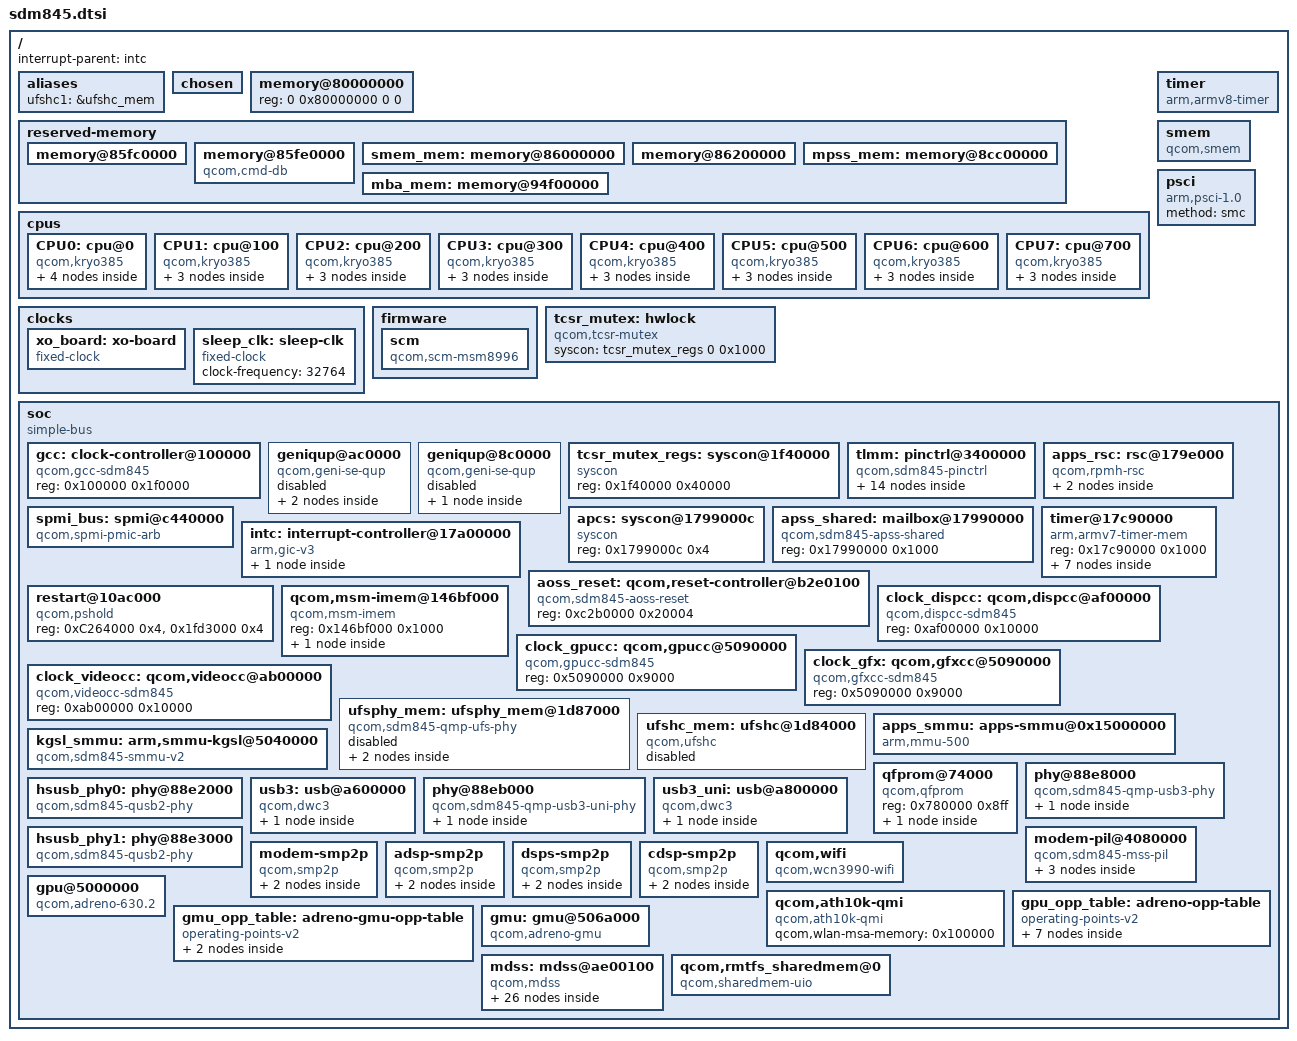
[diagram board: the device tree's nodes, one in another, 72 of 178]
// SPDX-License-Identifier: GPL-2.0
/*
 * SDM845 SoC device tree source
 *
 * Copyright (c) 2018, The Linux Foundation. All rights reserved.
 */

#include <dt-bindings/clock/qcom,gcc-sdm845.h>
#include <dt-bindings/interrupt-controller/arm-gic.h>
#include <dt-bindings/clock/qcom,rpmh.h>
#include <dt-bindings/clock/qcom,dispcc-sdm845.h>
#include <dt-bindings/clock/qcom,gpucc-sdm845.h>
#include <dt-bindings/clock/qcom,videocc-sdm845.h>
#include <dt-bindings/clock/qcom,rpmh.h>
#include <dt-bindings/regulator/qcom,rpmh-regulator.h>
#include <dt-bindings/spmi/spmi.h>
#include <dt-bindings/reset/qcom,sdm845-aoss.h>
#include <dt-bindings/soc/qcom,rpmh-rsc.h>
#include <dt-bindings/msm/msm-bus-ids.h>
#include <dt-bindings/phy/phy-qcom-qusb2.h>

/ {
	interrupt-parent = <&intc>;

	#address-cells = <2>;
	#size-cells = <2>;

	aliases {
		ufshc1 = &ufshc_mem; /* Embedded UFS slot */
	};

	chosen { };

	memory@80000000 {
		device_type = "memory";
		/* We expect the bootloader to fill in the size */
		reg = <0 0x80000000 0 0>;
	};
	reserved-memory {
		#address-cells = <2>;
		#size-cells = <2>;
		ranges;

		memory@85fc0000 {
			reg = <0 0x85fc0000 0 0x20000>;
			no-map;
		};

		memory@85fe0000 {
			compatible = "qcom,cmd-db";
			reg = <0x0 0x85fe0000 0x0 0x20000>;
			no-map;
		};

		smem_mem: memory@86000000 {
			reg = <0x0 0x86000000 0x0 0x200000>;
			no-map;
		};

		memory@86200000 {
			reg = <0 0x86200000 0 0x2d00000>;
			no-map;
		};

		mpss_mem: memory@8cc00000 {
			no-map;
			reg = <0 0x8e000000 0 0x7800000>;
		};

		mba_mem: memory@94f00000 {
			no-map;
			reg = <0 0x96500000 0 0x200000>;
		};
	};

	cpus {
		#address-cells = <2>;
		#size-cells = <0>;

		CPU0: cpu@0 {
			device_type = "cpu";
			compatible = "qcom,kryo385";
			reg = <0x0 0x0>;
			enable-method = "psci";
			efficiency = <1024>;
			next-level-cache = <&L2_0>;

			L2_0: l2-cache {
				compatible = "cache";
				next-level-cache = <&L3_0>;

				L3_0: l3-cache {
				      compatible = "cache";
				};
			};

			L1_I_0: l1-icache {
				compatible = "cache";
				qcom,dump-size = <0x9000>;
			};

			L1_D_0: l1-dcache {
				compatible = "cache";
				qcom,dump-size = <0x9000>;
			};
		};

		CPU1: cpu@100 {
			device_type = "cpu";
			compatible = "qcom,kryo385";
			reg = <0x0 0x100>;
			enable-method = "psci";
			efficiency = <1024>;
			next-level-cache = <&L2_100>;

			L2_100: l2-cache {
			      compatible = "cache";
			      next-level-cache = <&L3_0>;
			};

			L1_I_100: l1-icache {
				compatible = "cache";
				qcom,dump-size = <0x9000>;
			};

			L1_D_100: l1-dcache {
				compatible = "cache";
				qcom,dump-size = <0x9000>;
			};
		};

		CPU2: cpu@200 {
			device_type = "cpu";
			compatible = "qcom,kryo385";
			reg = <0x0 0x200>;
			enable-method = "psci";
			efficiency = <1024>;
			next-level-cache = <&L2_200>;

			L2_200: l2-cache {
			      compatible = "cache";
			      next-level-cache = <&L3_0>;
			};

			L1_I_200: l1-icache {
				compatible = "cache";
				qcom,dump-size = <0x9000>;
			};

			L1_D_200: l1-dcache {
				compatible = "cache";
				qcom,dump-size = <0x9000>;
			};
		};

		CPU3: cpu@300 {
			device_type = "cpu";
			compatible = "qcom,kryo385";
			reg = <0x0 0x300>;
			enable-method = "psci";
			efficiency = <1024>;
			next-level-cache = <&L2_300>;

			L2_300: l2-cache {
			      compatible = "cache";
			      next-level-cache = <&L3_0>;
			};

			L1_I_300: l1-icache {
				compatible = "cache";
				qcom,dump-size = <0x9000>;
			};
			L1_D_300: l1-dcache {
				compatible = "cache";
				qcom,dump-size = <0x9000>;
			};
		};

		CPU4: cpu@400 {
			device_type = "cpu";
			compatible = "qcom,kryo385";
			reg = <0x0 0x400>;
			enable-method = "psci";
			efficiency = <1740>;
			next-level-cache = <&L2_400>;

			L2_400: l2-cache {
			      compatible = "cache";
			      next-level-cache = <&L3_0>;
			};

			L1_I_400: l1-icache {
				compatible = "cache";
				qcom,dump-size = <0x12000>;
			};

			L1_D_400: l1-dcache {
				compatible = "cache";
				qcom,dump-size = <0x12000>;
			};
		};

		CPU5: cpu@500 {
			device_type = "cpu";
			compatible = "qcom,kryo385";
			reg = <0x0 0x500>;
			enable-method = "psci";
			efficiency = <1740>;
			next-level-cache = <&L2_500>;

			L2_500: l2-cache {
			      compatible = "cache";
			      next-level-cache = <&L3_0>;
			};

			L1_I_500: l1-icache {
				compatible = "cache";
				qcom,dump-size = <0x12000>;
			};

			L1_D_500: l1-dcache {
				compatible = "cache";
				qcom,dump-size = <0x12000>;
			};
		};

		CPU6: cpu@600 {
			device_type = "cpu";
			compatible = "qcom,kryo385";
			reg = <0x0 0x600>;
			enable-method = "psci";
			efficiency = <1740>;
			next-level-cache = <&L2_600>;

			L2_600: l2-cache {
			      compatible = "cache";
			      next-level-cache = <&L3_0>;
			};

			L1_I_600: l1-icache {
				compatible = "cache";
				qcom,dump-size = <0x12000>;
			};

			L1_D_600: l1-dcache {
				compatible = "cache";
				qcom,dump-size = <0x12000>;
			};
		};

		CPU7: cpu@700 {
			device_type = "cpu";
			compatible = "qcom,kryo385";
			reg = <0x0 0x700>;
			enable-method = "psci";
			efficiency = <1740>;
			next-level-cache = <&L2_700>;

			L2_700: l2-cache {
			      compatible = "cache";
			      next-level-cache = <&L3_0>;
			};

			L1_I_700: l1-icache {
				compatible = "cache";
				qcom,dump-size = <0x12000>;
			};

			L1_D_700: l1-dcache {
				compatible = "cache";
				qcom,dump-size = <0x12000>;
		};
		};
	};

	timer {
		compatible = "arm,armv8-timer";
		interrupts = <GIC_PPI 1 IRQ_TYPE_LEVEL_LOW>,
			     <GIC_PPI 2 IRQ_TYPE_LEVEL_LOW>,
			     <GIC_PPI 3 IRQ_TYPE_LEVEL_LOW>,
			     <GIC_PPI 0 IRQ_TYPE_LEVEL_LOW>;
	};

	clocks {
		xo_board: xo-board {
			compatible = "fixed-clock";
			#clock-cells = <0>;
			clock-frequency = <38400000>;
			clock-output-names = "xo_board";
		};

		sleep_clk: sleep-clk {
			compatible = "fixed-clock";
			#clock-cells = <0>;
			clock-frequency = <32764>;
		};
	};

	firmware {
		scm {
			compatible = "qcom,scm-msm8996";
		};
	};

	tcsr_mutex: hwlock {
		compatible = "qcom,tcsr-mutex";
		syscon = <&tcsr_mutex_regs 0 0x1000>;
		#hwlock-cells = <1>;
	};

	smem {
		compatible = "qcom,smem";
		memory-region = <&smem_mem>;
		hwlocks = <&tcsr_mutex 3>;
	};

	psci {
		compatible = "arm,psci-1.0";
		method = "smc";
	};

	soc: soc {
		#address-cells = <1>;
		#size-cells = <1>;
		ranges = <0 0 0 0xffffffff>;
		compatible = "simple-bus";

		gcc: clock-controller@100000 {
			compatible = "qcom,gcc-sdm845";
			reg = <0x100000 0x1f0000>;
			#clock-cells = <1>;
			#reset-cells = <1>;
			#power-domain-cells = <1>;
		};

		geniqup@ac0000 {
			compatible = "qcom,geni-se-qup";
			reg = <0xac0000 0x6000>;
			clock-names = "m-ahb", "s-ahb";
			clocks = <&gcc GCC_QUPV3_WRAP_1_M_AHB_CLK>,
				 <&gcc GCC_QUPV3_WRAP_1_S_AHB_CLK>;
			#address-cells = <1>;
			#size-cells = <1>;
			ranges;
			status = "disabled";

			uart2: serial@a84000 {
				compatible = "qcom,geni-debug-uart";
				reg = <0xa84000 0x4000>;
				clock-names = "se";
				clocks = <&gcc GCC_QUPV3_WRAP1_S1_CLK>;
				pinctrl-names = "default", "sleep";
				pinctrl-0 = <&qup_uart2_default>;
				pinctrl-1 = <&qup_uart2_sleep>;
				interrupts = <GIC_SPI 354 IRQ_TYPE_LEVEL_HIGH>;
				status = "disabled";
			};

			i2c10: i2c@a88000 {
				compatible = "qcom,geni-i2c";
				reg = <0xa88000 0x4000>;
				clock-names = "se";
				clocks = <&gcc GCC_QUPV3_WRAP1_S2_CLK>;
				pinctrl-names = "default", "sleep";
				pinctrl-0 = <&qup_i2c10_default>;
				pinctrl-1 = <&qup_i2c10_sleep>;
				interrupts = <GIC_SPI 355 IRQ_TYPE_LEVEL_HIGH>;
				#address-cells = <1>;
				#size-cells = <0>;
				status = "disabled";
			};
		};

		geniqup@8c0000 {
			compatible = "qcom,geni-se-qup";
			reg = <0x8c0000 0x6000>;
			clock-names = "m-ahb", "s-ahb";
			clocks = <&gcc GCC_QUPV3_WRAP_0_M_AHB_CLK>,
				<&gcc GCC_QUPV3_WRAP_0_S_AHB_CLK>;
			#address-cells = <1>;
			#size-cells = <1>;
			ranges;
			status = "disabled";

			uart6: serial@898000 {
				compatible = "qcom,geni-uart";
				reg = <0x898000 0x4000>;
				clock-names = "se";
				clocks = <&gcc GCC_QUPV3_WRAP0_S6_CLK>;
				interrupts = <GIC_SPI 607 IRQ_TYPE_LEVEL_HIGH>;
				pinctrl-names = "default", "sleep";
				pinctrl-0 = <&qup_uart6_default>;
				pinctrl-1 = <&qup_uart6_sleep>;
				status = "disabled";
			};
		};

		tcsr_mutex_regs: syscon@1f40000 {
			compatible = "syscon";
			reg = <0x1f40000 0x40000>;
		};

		tlmm: pinctrl@3400000 {
			compatible = "qcom,sdm845-pinctrl";
			reg = <0x03400000 0xc00000>;
			interrupts = <GIC_SPI 208 IRQ_TYPE_NONE>;
			gpio-controller;
			#gpio-cells = <2>;
			interrupt-controller;
			#interrupt-cells = <2>;

			qup_i2c10_default: qup-i2c10-default {
				pinmux {
					function = "qup10";
					pins = "gpio55", "gpio56";
				};
			};

			qup_i2c10_sleep: qup-i2c10-sleep {
				pinmux {
					function = "gpio";
					pins = "gpio55", "gpio56";
				};
			};

			qup_uart2_default: qup-uart2-default {
				pinmux {
					function = "qup9";
					pins = "gpio4", "gpio5";
				};
			};

			qup_uart2_sleep: qup-uart2-sleep {
				pinmux {
					function = "gpio";
					pins = "gpio4", "gpio5";
				};
			};

			qup_uart6_default: qup-uart6-default {
				pinmux {
					function = "qup6";
					pins = "gpio45", "gpio46",
							"gpio47", "gpio48";
				};

				pinconf {
					pins = "gpio45", "gpio46",
							"gpio47", "gpio48";
					drive-strength = <2>;
					bias-no-pull;
				};
			};

			qup_uart6_sleep: qup-uart6-sleep {
				pinmux {
					function = "gpio";
					pins = "gpio45", "gpio46",
							"gpio47", "gpio48";
				};

				pinconf_ctsrx {
					pins = "gpio45", "gpio46",
							"gpio47", "gpio48";
					bias-no-pull;
				};
			};
		};

	        apps_rsc: rsc@179e000 {
			compatible = "qcom,rpmh-rsc";
			label = "apps_rsc";
			reg = <0x179e0000 0x100>, <0x179e0d00 0x3000>;
			reg-names = "drv", "tcs";
			interrupts = <GIC_SPI 5 IRQ_TYPE_LEVEL_HIGH>;
			qcom,drv-id = <2>;
			qcom,tcs-config = <ACTIVE_TCS  2>,
					  <SLEEP_TCS   3>,
					  <WAKE_TCS    3>,
					  <CONTROL_TCS 1>;

			msm_bus_apps_rsc {
				compatible = "qcom,msm-bus-rsc";
				qcom,msm-bus-id = <MSM_BUS_RSC_APPS>;
			};
		};

		spmi_bus: spmi@c440000 {
			compatible = "qcom,spmi-pmic-arb";
			reg = <0xc440000 0x1100>,
			      <0xc600000 0x2000000>,
			      <0xe600000 0x100000>,
			      <0xe700000 0xa0000>,
			      <0xc40a000 0x26000>;
			reg-names = "core", "chnls", "obsrvr", "intr", "cnfg";
			interrupt-names = "periph_irq";
			interrupts = <GIC_SPI 481 IRQ_TYPE_LEVEL_HIGH>;
			qcom,ee = <0>;
			qcom,channel = <0>;
			#address-cells = <2>;
			#size-cells = <0>;
			interrupt-controller;
			#interrupt-cells = <4>;
			cell-index = <0>;
		};

		apcs: syscon@1799000c {
			compatible = "syscon";
			reg = <0x1799000c 0x4>;
		};

		apss_shared: mailbox@17990000 {
			compatible = "qcom,sdm845-apss-shared";
			reg = <0x17990000 0x1000>;
			#mbox-cells = <1>;
		};

		intc: interrupt-controller@17a00000 {
			compatible = "arm,gic-v3";
			#address-cells = <1>;
			#size-cells = <1>;
			ranges;
			#interrupt-cells = <3>;
			interrupt-controller;
			reg = <0x17a00000 0x10000>,     /* GICD */
			      <0x17a60000 0x100000>;    /* GICR * 8 */
			interrupts = <GIC_PPI 9 IRQ_TYPE_LEVEL_HIGH>;

			gic-its@17a40000 {
				compatible = "arm,gic-v3-its";
				msi-controller;
				#msi-cells = <1>;
				reg = <0x17a40000 0x20000>;
				status = "disabled";
			};
		};

		timer@17c90000 {
			#address-cells = <1>;
			#size-cells = <1>;
			ranges;
			compatible = "arm,armv7-timer-mem";
			reg = <0x17c90000 0x1000>;

			frame@17ca0000 {
				frame-number = <0>;
				interrupts = <GIC_SPI 7 IRQ_TYPE_LEVEL_HIGH>,
					     <GIC_SPI 6 IRQ_TYPE_LEVEL_HIGH>;
				reg = <0x17ca0000 0x1000>,
				      <0x17cb0000 0x1000>;
			};

			frame@17cc0000 {
				frame-number = <1>;
				interrupts = <GIC_SPI 8 IRQ_TYPE_LEVEL_HIGH>;
				reg = <0x17cc0000 0x1000>;
				status = "disabled";
			};

			frame@17cd0000 {
				frame-number = <2>;
				interrupts = <GIC_SPI 9 IRQ_TYPE_LEVEL_HIGH>;
				reg = <0x17cd0000 0x1000>;
				status = "disabled";
			};

			frame@17ce0000 {
				frame-number = <3>;
				interrupts = <GIC_SPI 10 IRQ_TYPE_LEVEL_HIGH>;
				reg = <0x17ce0000 0x1000>;
				status = "disabled";
			};

			frame@17cf0000 {
				frame-number = <4>;
				interrupts = <GIC_SPI 11 IRQ_TYPE_LEVEL_HIGH>;
				reg = <0x17cf0000 0x1000>;
				status = "disabled";
			};

			frame@17d00000 {
				frame-number = <5>;
				interrupts = <GIC_SPI 12 IRQ_TYPE_LEVEL_HIGH>;
				reg = <0x17d00000 0x1000>;
				status = "disabled";
			};

			frame@17d10000 {
				frame-number = <6>;
				interrupts = <GIC_SPI 13 IRQ_TYPE_LEVEL_HIGH>;
				reg = <0x17d10000 0x1000>;
				status = "disabled";
			};
		};

		aoss_reset: qcom,reset-controller@b2e0100 {
			compatible = "qcom,sdm845-aoss-reset";
			reg = <0xc2b0000 0x20004>;
			#reset-cells = <1>;
		};

	restart@10ac000 {
		compatible = "qcom,pshold";
		reg = <0xC264000 0x4>,
		      <0x1fd3000 0x4>;
		reg-names = "pshold-base", "tcsr-boot-misc-detect";
	};

	qcom,msm-imem@146bf000 {
		compatible = "qcom,msm-imem";
		reg = <0x146bf000 0x1000>;
		ranges = <0x0 0x146bf000 0x1000>;
		#address-cells = <1>;
		#size-cells = <1>;

		restart_reason@65c {
			compatible = "qcom,msm-imem-restart_reason";
			reg = <0x65c 4>;
		};
	};

		clock_dispcc: qcom,dispcc@af00000 {
			compatible = "qcom,dispcc-sdm845", "syscon";
			reg = <0xaf00000 0x10000>;
			reg-names = "cc_base";
			#clock-cells = <1>;
			#reset-cells = <1>;
			#power-domain-cells = <1>;
		};

		clock_gpucc: qcom,gpucc@5090000 {
			compatible = "qcom,gpucc-sdm845", "syscon";
			reg = <0x5090000 0x9000>;
			reg-names = "cc_base";
			#clock-cells = <1>;
			#reset-cells = <1>;
			#power-domain-cells = <1>;
		};

		clock_gfx: qcom,gfxcc@5090000 {
			compatible = "qcom,gfxcc-sdm845";
			reg = <0x5090000 0x9000>;
			reg-names = "cc_base";
			#clock-cells = <1>;
			#reset-cells = <1>;
		};

		clock_videocc: qcom,videocc@ab00000 {
			compatible = "qcom,videocc-sdm845", "syscon";
			reg = <0xab00000 0x10000>;
			reg-names = "cc_base";
			#clock-cells = <1>;
			#reset-cells = <1>;
			#power-domain-cells = <1>;
		};

		ufsphy_mem: ufsphy_mem@1d87000 {
			compatible = "qcom,sdm845-qmp-ufs-phy";
			reg = <0x1d87000 0x18c>; /* PHY regs */
			#clock-cells = <1>;
			#address-cells = <1>;
			#size-cells = <1>;
			ranges;
			clock-names = "ref_clk_src",
				"ref_clk",
				"ref_aux_clk";
			clocks = <&clock_rpmh RPMH_CXO_CLK>,
				<&gcc GCC_UFS_MEM_CLKREF_CLK>,
				<&gcc GCC_UFS_PHY_PHY_AUX_CLK>;

			status = "disabled";

			ufsphy_0: lane@0x1d87400 {
				reg = <0x1d87400 0x108>,
					<0x1d87600 0x1e0>,
					<0x1d87c00 0x1dc>;
				#phy-cells = <0>;
			};

			ufsphy_1: lane@0x1d87800 {
				reg = <0x1d87800 0x108>,
					<0x1d87a00 0x1e0>,
					<0x1d87c00 0x1dc>;
				#phy-cells = <0>;
			};
		};

		ufshc_mem: ufshc@1d84000 {
			compatible = "qcom,ufshc";
			reg = <0x1d84000 0x2500>;
			interrupts = <0 265 0>;
			phys = <&ufsphy_0>, <&ufsphy_1>;
			phy-names = "ufsphy_0", "ufsphy_1";

			lanes-per-direction = <2>;
			dev-ref-clk-freq = <0>; /* 19.2 MHz */

			power-domains = <&gcc UFS_PHY_GDSC>;

			clock-names =
				"core_clk",
				"bus_aggr_clk",
				"iface_clk",
				"core_clk_unipro",
				"ref_clk",
				"tx_lane0_sync_clk",
				"rx_lane0_sync_clk",
				"rx_lane1_sync_clk";
			clocks =
				<&gcc GCC_UFS_PHY_AXI_CLK>,
				<&gcc GCC_AGGRE_UFS_PHY_AXI_CLK>,
				<&gcc GCC_UFS_PHY_AHB_CLK>,
				<&gcc GCC_UFS_PHY_UNIPRO_CORE_CLK>,
				<&clock_rpmh RPMH_CXO_CLK>,
				<&gcc GCC_UFS_PHY_TX_SYMBOL_0_CLK>,
				<&gcc GCC_UFS_PHY_RX_SYMBOL_0_CLK>,
				<&gcc GCC_UFS_PHY_RX_SYMBOL_1_CLK>;
			freq-table-hz =
				<50000000 200000000>,
				<0 0>,
				<0 0>,
				<37500000 150000000>,
				<0 0>,
				<0 0>,
				<0 0>,
				<0 0>;

			non-removable;
			pinctrl-names = "dev-reset-assert", "dev-reset-deassert";
			pinctrl-0 = <&ufs_dev_reset_assert>;
			pinctrl-1 = <&ufs_dev_reset_deassert>;

			resets = <&gcc GCC_UFS_PHY_BCR>;
			reset-names = "core_reset";

			status = "disabled";
		};

		apps_smmu: apps-smmu@0x15000000 {
			compatible = "arm,mmu-500";
			reg = <0x15000000 0x80000>;
			#iommu-cells = <2>;
			#global-interrupts = <1>;

			interrupts =	<GIC_SPI 65 IRQ_TYPE_LEVEL_HIGH>,
					<GIC_SPI 96 IRQ_TYPE_LEVEL_HIGH>,
					<GIC_SPI 97 IRQ_TYPE_LEVEL_HIGH>,
					<GIC_SPI 98 IRQ_TYPE_LEVEL_HIGH>,
					<GIC_SPI 99 IRQ_TYPE_LEVEL_HIGH>,
					<GIC_SPI 100 IRQ_TYPE_LEVEL_HIGH>,
					<GIC_SPI 101 IRQ_TYPE_LEVEL_HIGH>,
					<GIC_SPI 102 IRQ_TYPE_LEVEL_HIGH>,
					<GIC_SPI 103 IRQ_TYPE_LEVEL_HIGH>,
					<GIC_SPI 104 IRQ_TYPE_LEVEL_HIGH>,
					<GIC_SPI 105 IRQ_TYPE_LEVEL_HIGH>,
					<GIC_SPI 106 IRQ_TYPE_LEVEL_HIGH>,
					<GIC_SPI 107 IRQ_TYPE_LEVEL_HIGH>,
					<GIC_SPI 108 IRQ_TYPE_LEVEL_HIGH>,
					<GIC_SPI 109 IRQ_TYPE_LEVEL_HIGH>,
					<GIC_SPI 110 IRQ_TYPE_LEVEL_HIGH>,
					<GIC_SPI 111 IRQ_TYPE_LEVEL_HIGH>,
					<GIC_SPI 112 IRQ_TYPE_LEVEL_HIGH>,
					<GIC_SPI 113 IRQ_TYPE_LEVEL_HIGH>,
					<GIC_SPI 114 IRQ_TYPE_LEVEL_HIGH>,
					<GIC_SPI 115 IRQ_TYPE_LEVEL_HIGH>,
					<GIC_SPI 116 IRQ_TYPE_LEVEL_HIGH>,
					<GIC_SPI 117 IRQ_TYPE_LEVEL_HIGH>,
					<GIC_SPI 118 IRQ_TYPE_LEVEL_HIGH>,
					<GIC_SPI 181 IRQ_TYPE_LEVEL_HIGH>,
					<GIC_SPI 182 IRQ_TYPE_LEVEL_HIGH>,
					<GIC_SPI 183 IRQ_TYPE_LEVEL_HIGH>,
					<GIC_SPI 184 IRQ_TYPE_LEVEL_HIGH>,
					<GIC_SPI 185 IRQ_TYPE_LEVEL_HIGH>,
					<GIC_SPI 186 IRQ_TYPE_LEVEL_HIGH>,
					<GIC_SPI 187 IRQ_TYPE_LEVEL_HIGH>,
					<GIC_SPI 188 IRQ_TYPE_LEVEL_HIGH>,
					<GIC_SPI 189 IRQ_TYPE_LEVEL_HIGH>,
					<GIC_SPI 190 IRQ_TYPE_LEVEL_HIGH>,
					<GIC_SPI 191 IRQ_TYPE_LEVEL_HIGH>,
					<GIC_SPI 192 IRQ_TYPE_LEVEL_HIGH>,
					<GIC_SPI 315 IRQ_TYPE_LEVEL_HIGH>,
					<GIC_SPI 316 IRQ_TYPE_LEVEL_HIGH>,
					<GIC_SPI 317 IRQ_TYPE_LEVEL_HIGH>,
					<GIC_SPI 318 IRQ_TYPE_LEVEL_HIGH>,
					<GIC_SPI 319 IRQ_TYPE_LEVEL_HIGH>,
					<GIC_SPI 320 IRQ_TYPE_LEVEL_HIGH>,
					<GIC_SPI 321 IRQ_TYPE_LEVEL_HIGH>,
					<GIC_SPI 322 IRQ_TYPE_LEVEL_HIGH>,
					<GIC_SPI 323 IRQ_TYPE_LEVEL_HIGH>,
					<GIC_SPI 324 IRQ_TYPE_LEVEL_HIGH>,
					<GIC_SPI 325 IRQ_TYPE_LEVEL_HIGH>,
					<GIC_SPI 326 IRQ_TYPE_LEVEL_HIGH>,
					<GIC_SPI 327 IRQ_TYPE_LEVEL_HIGH>,
					<GIC_SPI 328 IRQ_TYPE_LEVEL_HIGH>,
					<GIC_SPI 329 IRQ_TYPE_LEVEL_HIGH>,
					<GIC_SPI 330 IRQ_TYPE_LEVEL_HIGH>,
					<GIC_SPI 331 IRQ_TYPE_LEVEL_HIGH>,
					<GIC_SPI 332 IRQ_TYPE_LEVEL_HIGH>,
					<GIC_SPI 333 IRQ_TYPE_LEVEL_HIGH>,
					<GIC_SPI 334 IRQ_TYPE_LEVEL_HIGH>,
					<GIC_SPI 335 IRQ_TYPE_LEVEL_HIGH>,
					<GIC_SPI 336 IRQ_TYPE_LEVEL_HIGH>,
					<GIC_SPI 337 IRQ_TYPE_LEVEL_HIGH>,
					<GIC_SPI 338 IRQ_TYPE_LEVEL_HIGH>,
					<GIC_SPI 339 IRQ_TYPE_LEVEL_HIGH>,
					<GIC_SPI 340 IRQ_TYPE_LEVEL_HIGH>,
					<GIC_SPI 341 IRQ_TYPE_LEVEL_HIGH>,
					<GIC_SPI 342 IRQ_TYPE_LEVEL_HIGH>,
					<GIC_SPI 343 IRQ_TYPE_LEVEL_HIGH>;
		};

		kgsl_smmu: arm,smmu-kgsl@5040000 {
			compatible = "qcom,sdm845-smmu-v2", "qcom,smmu-v2";
			reg = <0x5040000 0x10000>;
			#iommu-cells = <1>;
			#global-interrupts = <2>;
			interrupts = <GIC_SPI 229 IRQ_TYPE_LEVEL_HIGH>,
					<GIC_SPI 231 IRQ_TYPE_LEVEL_HIGH>,
					<GIC_SPI 364 IRQ_TYPE_EDGE_RISING>,
					<GIC_SPI 365 IRQ_TYPE_EDGE_RISING>,
					<GIC_SPI 366 IRQ_TYPE_EDGE_RISING>,
					<GIC_SPI 367 IRQ_TYPE_EDGE_RISING>,
					<GIC_SPI 368 IRQ_TYPE_EDGE_RISING>,
					<GIC_SPI 369 IRQ_TYPE_EDGE_RISING>,
					<GIC_SPI 370 IRQ_TYPE_EDGE_RISING>,
					<GIC_SPI 371 IRQ_TYPE_EDGE_RISING>;
			clocks = <&gcc GCC_GPU_MEMNOC_GFX_CLK>,
				<&gcc GCC_GPU_CFG_AHB_CLK>;
			clock-names = "bus", "iface";

			power-domains = <&clock_gpucc GPU_CX_GDSC>;
		};

		qfprom@74000 {
			compatible = "qcom,qfprom";
			reg = <0x780000 0x8ff>;
			#address-cells = <1>;
			#size-cells = <1>;
			qusb2p_hstx_trim: hstx_trim@1eb {
				reg = <0x1eb 0x1>;
				bits = <1 4>;
			};
		};

		phy@88e8000 {
			compatible = "qcom,sdm845-qmp-usb3-phy";
			reg = <0x88e9000 0x18c>,
				<0x88e8000 0x10>; /*dp_com */
			reg-names = "reg-base", "dp_com";
			#clock-cells = <1>;
			#address-cells = <1>;
			#size-cells = <1>;
			ranges;

			clocks = <&gcc GCC_USB3_PRIM_PHY_AUX_CLK>,
				<&gcc GCC_USB_PHY_CFG_AHB2PHY_CLK>,
				<&gcc GCC_USB3_PRIM_CLKREF_CLK>,
				<&gcc GCC_USB3_PRIM_PHY_COM_AUX_CLK>;

			clock-names = "aux", "cfg_ahb", "ref", "com_aux";

			vdda-phy-supply = <&pm8998_l26>;
			vdda-pll-supply = <&pm8998_l1>;

			resets = <&gcc GCC_USB3_DP_PHY_PRIM_BCR>,
				<&gcc GCC_USB3_PHY_PRIM_BCR>;
			reset-names = "phy", "common";

			ssusb_phy_0: lane@88e9200 {
				reg = <0x88e9200 0x128>,
					<0x88e9400 0x200>,
					<0x88e9c00 0x218>,
					<0x88e9a00 0x100>;
				reg-names = "tx", "rx", "pcs", "pcs_misc";
				#phy-cells = <0>;
				clocks = <&gcc GCC_USB3_PRIM_PHY_PIPE_CLK>;
				clock-names = "pipe0";
				clock-output-names = "usb3_phy_pipe_clk_src";
			};
		};

		hsusb_phy0: phy@88e2000 {
			compatible = "qcom,sdm845-qusb2-phy";
			reg = <0x88e2000 0x400>;
			reg-names = "reg-base";
			#phy-cells = <0>;

			clocks = <&gcc GCC_USB_PHY_CFG_AHB2PHY_CLK>,
				<&clock_rpmh RPMH_CXO_CLK>;
			clock-names = "cfg_ahb", "ref";

			vdd-supply = <&pm8998_l1>;
			vdda-pll-supply = <&pm8998_l12>;
			vdda-phy-dpdm-supply = <&pm8998_l24>;
			resets = <&gcc GCC_QUSB2PHY_PRIM_BCR>;
			nvmem-cells = <&qusb2p_hstx_trim>;

			qcom,imp-res-offset-value = <8>;
			qcom,hstx-trim-value = <QUSB2_V2_HSTX_TRIM_21_6_MA>;
			qcom,preemphasis-level = <QUSB2_V2_PREEMPHASIS_5_PERCENT>;
			qcom,preemphasis-width = <QUSB2_V2_PREEMPHASIS_WIDTH_HALF_BIT>;
		};

		usb3: usb@a600000 {
			compatible = "qcom,dwc3";
			reg = <0xa6f8800 0x400>;
			reg-names = "qscratch";
			#address-cells = <1>;
			#size-cells = <1>;
			ranges;

			interrupts = <0 131 0>, <0 486 0>, <0 488 0>, <0 489 0>;
			interrupt-names = "hs_phy_irq", "ss_phy_irq",
					  "dm_hs_phy_irq", "dp_hs_phy_irq";

			clocks = <&gcc GCC_CFG_NOC_USB3_PRIM_AXI_CLK>,
				<&gcc GCC_USB30_PRIM_MASTER_CLK>,
				<&gcc GCC_AGGRE_USB3_PRIM_AXI_CLK>,
				<&gcc GCC_USB30_PRIM_MOCK_UTMI_CLK>,
				<&gcc GCC_USB30_PRIM_SLEEP_CLK>,
				<&gcc GCC_USB_PHY_CFG_AHB2PHY_CLK>,
				<&gcc GCC_USB3_PRIM_CLKREF_CLK>;
			clock-names = "cfg_noc", "core", "aggr_noc", "utmi",
					"sleep", "cfg_ahb", "ref";

			assigned-clocks = <&gcc GCC_USB30_PRIM_MOCK_UTMI_CLK>,
					  <&gcc GCC_USB30_PRIM_MASTER_CLK>;
			assigned-clock-rates = <19200000>, <150000000>;

			resets = <&gcc GCC_USB30_PRIM_BCR>;
			reset-names = "core_reset";
			power-domains = <&gcc USB30_PRIM_GDSC>;

			dwc3@6a00000 {
				compatible = "snps,dwc3";
				reg = <0xa600000 0xcd00>;
				interrupts = <0 133 0>;
				snps,disable-clk-gating;
				snps,dis_u2_susphy_quirk;
				snps,dis_enblslpm_quirk;
				phys = <&hsusb_phy0>, <&ssusb_phy_0>;
				phy-names = "usb2-phy", "usb3-phy";
				dr_mode = "host";
			};
		};

		phy@88eb000 {
			compatible = "qcom,sdm845-qmp-usb3-uni-phy";
			reg = <0x88eb000 0x18c>;
			reg-names = "reg-base";
			#clock-cells = <1>;
			#address-cells = <1>;
			#size-cells = <1>;
			ranges;

			clocks = <&gcc GCC_USB3_SEC_PHY_AUX_CLK>,
				<&gcc GCC_USB_PHY_CFG_AHB2PHY_CLK>,
				<&gcc GCC_USB3_SEC_CLKREF_CLK>,
				<&gcc GCC_USB3_SEC_PHY_COM_AUX_CLK>;

			clock-names = "aux", "cfg_ahb", "ref", "com_aux";

			vdda-phy-supply = <&pm8998_l26>;
			vdda-pll-supply = <&pm8998_l1>;

			resets = <&gcc GCC_USB3PHY_PHY_SEC_BCR>,
				<&gcc GCC_USB3_PHY_SEC_BCR>;
			reset-names = "phy", "common";

			ssusb_phy_1: lane@88eb200 {
				reg = <0x88eb200 0x128>,
					<0x88eb400 0x1fc>,
					<0x88eb800 0x218>,
					<0x88eb600 0x70>;
				reg-names = "tx", "rx", "pcs", "pcs_misc";
				#phy-cells = <0>;
				clocks = <&gcc GCC_USB3_SEC_PHY_PIPE_CLK>;
				clock-names = "pipe0";
				clock-output-names = "usb3_uniphy_pipe_clk_src";
			};
		};

		hsusb_phy1: phy@88e3000 {
			compatible = "qcom,sdm845-qusb2-phy";
			reg = <0x88e3000 0x400>;
			reg-names = "reg-base";
			#phy-cells = <0>;

			clocks = <&gcc GCC_USB_PHY_CFG_AHB2PHY_CLK>,
				<&clock_rpmh RPMH_CXO_CLK>;
			clock-names = "cfg_ahb", "ref";

			vdd-supply = <&pm8998_l1>;
			vdda-pll-supply = <&pm8998_l12>;
			vdda-phy-dpdm-supply = <&pm8998_l24>;

			resets = <&gcc GCC_QUSB2PHY_SEC_BCR>;

			qcom,imp-res-offset-value = <8>;
			qcom,hstx-trim-value = <QUSB2_V2_HSTX_TRIM_22_8_MA>;
		};

		/* USB3 Secondary controller with QMP UNI-PHY */
		usb3_uni: usb@a800000 {
			compatible = "qcom,dwc3";
			reg = <0xa8f8800 0x400>;
			reg-names = "qscratch";
			#address-cells = <1>;
			#size-cells = <1>;
			ranges;

			interrupts = <0 136 0>, <0 487 0>, <0 490 0>, <0 491 0>;
			interrupt-names = "hs_phy_irq", "ss_phy_irq",
					  "dm_hs_phy_irq", "dp_hs_phy_irq";

			clocks = <&gcc GCC_CFG_NOC_USB3_SEC_AXI_CLK>,
				<&gcc GCC_USB30_SEC_MASTER_CLK>,
				<&gcc GCC_AGGRE_USB3_SEC_AXI_CLK>,
				<&gcc GCC_USB30_SEC_MOCK_UTMI_CLK>,
				<&gcc GCC_USB30_SEC_SLEEP_CLK>,
				<&gcc GCC_USB_PHY_CFG_AHB2PHY_CLK>,
				<&gcc GCC_USB3_SEC_CLKREF_CLK>;
			clock-names = "cfg_noc", "core", "aggr_noc", "utmi",
					"sleep", "cfg_ahb", "ref";

			assigned-clocks = <&gcc GCC_USB30_SEC_MOCK_UTMI_CLK>,
					  <&gcc GCC_USB30_SEC_MASTER_CLK>;
			assigned-clock-rates = <19200000>, <150000000>;

			resets = <&gcc GCC_USB30_SEC_BCR>;
			reset-names = "core_reset";
			power-domains = <&gcc USB30_SEC_GDSC>;

			dwc3@a800000 {
				compatible = "snps,dwc3";
				reg = <0xa800000 0xcd00>;
				interrupts = <0 138 0>;
				snps,disable-clk-gating;
				snps,dis_u2_susphy_quirk;
				snps,dis_enblslpm_quirk;
				phys = <&hsusb_phy1>, <&ssusb_phy_1>;
				phy-names = "usb2-phy", "usb3-phy";
				dr_mode = "peripheral";
			};
		};

		modem-pil@4080000 {
			compatible = "qcom,sdm845-mss-pil";
			reg = <0x04080000 0x408>, <0x04180000 0x48>;

			reg-names = "qdsp6", "rmb";

			interrupts-extended = <&intc 0 266 1>,
					      <&modem_smp2p_in 0 0>,
					      <&modem_smp2p_in 1 0>,
					      <&modem_smp2p_in 2 0>,
					      <&modem_smp2p_in 3 0>;

			interrupt-names = "wdog", "fatal", "ready",
					  "handover", "stop-ack";

			clocks = <&gcc GCC_MSS_CFG_AHB_CLK>,
				 <&gcc GCC_MSS_Q6_MEMNOC_AXI_CLK>,
				 <&gcc GCC_BOOT_ROM_AHB_CLK>,
				 <&gcc GCC_MSS_GPLL0_DIV_CLK_SRC>,
				 <&gcc GCC_MSS_SNOC_AXI_CLK>,
				 <&gcc GCC_MSS_AXIS2_CLK>,
				 <&gcc GCC_MSS_MFAB_AXIS_CLK>,
				 <&gcc GCC_PRNG_AHB_CLK>,
				 <&xo_board>;

			clock-names = "iface", "bus", "mem", "gpll0_mss",
				      "snoc_axi", "axis2", "mnoc_axi",
				      "prng", "xo";

			qcom,smem-states = <&modem_smp2p_out 0>;
			qcom,smem-state-names = "stop";

			resets = <&aoss_reset AOSS_CC_MSS_RESTART>;
			reset-names = "mss_restart";

			cx-supply = <&pm8998_s9_level>;
			mx-supply = <&pm8998_s6_level>;
			mss-supply = <&pm8005_s2_level>;

			qcom,halt-regs = <&tcsr_mutex_regs
						0x23000 0x25000 0x24000>;

			mba {
				memory-region = <&mba_mem>;
			};

			mpss {
				memory-region = <&mpss_mem>;
			};

			glink-edge {
				interrupts = <0 449 IRQ_TYPE_EDGE_RISING>;
				label = "modem";
				qcom,remote-pid = <1>;
				mboxes = <&apss_shared 12>;
				mbox-names = "mpss_smem";
			};
		};

		modem-smp2p {
			compatible = "qcom,smp2p";
			qcom,smem = <435>, <428>;
			interrupts = <GIC_SPI 451 IRQ_TYPE_EDGE_RISING>;
			qcom,ipc = <&apcs 0 14>;
			qcom,local-pid = <0>;
			qcom,remote-pid = <1>;

			modem_smp2p_out: master-kernel {
				qcom,entry-name = "master-kernel";
				#qcom,smem-state-cells = <1>;
			};

			modem_smp2p_in: slave-kernel {
				qcom,entry-name = "slave-kernel";
				interrupt-controller;
				#interrupt-cells = <2>;
			};
		};

		adsp-smp2p {
			compatible = "qcom,smp2p";
			qcom,smem = <443>, <429>;
			interrupts = <GIC_SPI 158 IRQ_TYPE_EDGE_RISING>;
			qcom,ipc = <&apcs 0 10>;
			qcom,local-pid = <0>;
			qcom,remote-pid = <2>;

			adsp_smp2p_out: master-kernel {
				qcom,entry-name = "master-kernel";
				#qcom,smem-state-cells = <1>;
			};

			adsp_smp2p_in: slave-kernel {
				qcom,entry-name = "slave-kernel";
				interrupt-controller;
				#interrupt-cells = <2>;
			};
		};

		dsps-smp2p {
			compatible = "qcom,smp2p";
			qcom,smem = <481>, <430>;
			interrupts = <GIC_SPI 172 IRQ_TYPE_EDGE_RISING>;
			qcom,ipc = <&apcs 0 26>;
			qcom,local-pid = <0>;
			qcom,remote-pid = <3>;

			dsps_smp2p_out: master-kernel {
				qcom,entry-name = "master-kernel";
				#qcom,smem-state-cells = <1>;
			};

			dsps_smp2p_in: slave-kernel {
				qcom,entry-name = "slave-kernel";
				interrupt-controller;
				#interrupt-cells = <2>;
			};
		};

		cdsp-smp2p {
			compatible = "qcom,smp2p";
			qcom,smem = <94>, <432>;
			interrupts = <GIC_SPI 576 IRQ_TYPE_EDGE_RISING>;
			qcom,ipc = <&apcs 0 6>;
			qcom,local-pid = <0>;
			qcom,remote-pid = <5>;

			cdsp_smp2p_out: master-kernel {
				qcom,entry-name = "master-kernel";
				#qcom,smem-state-cells = <1>;
			};

			cdsp_smp2p_in: slave-kernel {
				qcom,entry-name = "slave-kernel";
				interrupt-controller;
				#interrupt-cells = <2>;
			};
		};

		qcom,wifi {
			compatible = "qcom,wcn3990-wifi";
			reg = <0x18800000 0x800000>,
			      <0xa0000000 0x10000000>;
			reg-names = "membase", "iommu_iova_base";
			iommus = <&apps_smmu 0x0040 0x1>;
			iommu-bypass;
			interrupts =
				<0 413 0 /* CE0 */ >,
				<0 414 0 /* CE1 */ >,
				<0 415 0 /* CE2 */ >,
				<0 416 0 /* CE3 */ >,
				<0 417 0 /* CE4 */ >,
				<0 418 0 /* CE5 */ >,
				<0 420 0 /* CE6 */ >,
				<0 421 0 /* CE7 */ >,
				<0 422 0 /* CE8 */ >,
				<0 423 0 /* CE9 */ >,
				<0 424 0 /* CE10 */ >,
				<0 425 0 /* CE11 */ >;
			vdd-0.8-cx-mx-supply = <&pm8998_l5>;
			vdd-1.8-xo-supply = <&pm8998_l7>;
			vdd-1.3-rfa-supply = <&pm8998_l17>;
			vdd-3.3-ch0-supply = <&pm8998_l25>;
			qcom,vdd-0.8-cx-mx-config = <800000 800000>;
			qcom,vdd-3.3-ch0-config = <3104000 3312000>;
		};

		qcom,ath10k-qmi {
			compatible = "qcom,ath10k-qmi";
			qcom,wlan-msa-memory = <0x100000>;
		};
		gpu_opp_table: adreno-opp-table {
			compatible = "operating-points-v2";

			opp-710000000 {
				opp-hz = /bits/ 64 <710000000>;
				qcom,level = <416>;
			};

			opp-675000000 {
				opp-hz = /bits/ 64 <675000000>;
				qcom,level = <384>;
			};

			opp-596000000 {
				opp-hz = /bits/ 64 <596000000>;
				qcom,level = <320>;
			};

			opp-520000000 {
				opp-hz = /bits/ 64 <520000000>;
				qcom,level = <256>;
			};

			opp-414000000 {
				opp-hz = /bits/ 64 <414000000>;
				qcom,level = <192>;
			};

			opp-342000000 {
				opp-hz = /bits/ 64 <342000000>;
				qcom,level = <128>;
			};

			opp-257000000 {
				opp-hz = /bits/ 64 <257000000>;
				qcom,level = <64>;
			};
		};

		gpu@5000000 {
			compatible = "qcom,adreno-630.2", "qcom,adreno";
			#stream-id-cells = <16>;

			reg = <0x5000000 0x40000>;
			reg-names = "kgsl_3d0_reg_memory";

			/*
			 * Look ma, no clocks! The GPU clocks and power are
			 * controlled entirely by the GMU
			 */

			interrupts = <0 300 0>;
			interrupt-names = "kgsl_3d0_irq";

			iommus = <&kgsl_smmu 0>;

			operating-points-v2 = <&gpu_opp_table>;

			gmu = <&gmu>;
		};

		gmu_opp_table: adreno-gmu-opp-table {
			compatible = "operating-points-v2";

			opp-400000000 {
				opp-hz = /bits/ 64 <400000000>;
				qcom,level = <128>;
			};

			opp-200000000 {
				opp-hz = /bits/ 64 <200000000>;
				qcom,level = <48>;
			};
		};

		gmu: gmu@506a000 {
			compatible="qcom,adreno-gmu";

			reg = <0x506a000 0x30000>, <0xb200000 0x300000>;
			reg-names = "gmu", "gmu_pdc";

			interrupts = <GIC_SPI 304 IRQ_TYPE_LEVEL_HIGH>,
				     <GIC_SPI 305 IRQ_TYPE_LEVEL_HIGH>;
			interrupt-names = "hfi", "gmu";

			clocks = <&clock_gpucc GPU_CC_CX_GMU_CLK>,
				<&clock_gpucc GPU_CC_CXO_CLK>,
				<&gcc GCC_DDRSS_GPU_AXI_CLK>,
				<&gcc GCC_GPU_MEMNOC_GFX_CLK>;
			clock-names = "gmu", "cxo", "axi", "memnoc";

			power-domains = <&clock_gpucc GPU_CX_GDSC>;
			iommus = <&kgsl_smmu 5>;

			operating-points-v2 = <&gmu_opp_table>;
		};
		
		mdss: mdss@ae00100 {
			compatible = "qcom,mdss";
			reg = <0xae00000 0x1000>,
			      <0xaeb0000 0x3000>,
			      <0xaeb8000 0x3000>;
			reg-names = "mdss_phys",
				    "vbif_phys",
				    "vbif_nrt_phys";

			power-domains = <&clock_dispcc 0>;
/*
			interrupts = <GIC_SPI 83 IRQ_TYPE_LEVEL_HIGH>;
			interrupt-controller;
			#interrupt-cells = <1>;
*/
			//clocks = <&mmcc MDSS_AHB_CLK>;
			//clock-names = "iface_clk";
			clocks = <&gcc GCC_DISP_AHB_CLK>,
				 <&gcc GCC_DISP_AXI_CLK>;
			clock-names = "iface", "bus";

			#address-cells = <1>;
			#size-cells = <1>;
			ranges;

			mdss_mdp: mdp@ae00000 {
				compatible = "qcom,dpu-kms";
				reg = <0x0ae00000 0x81d40>,
				      <0x0aeb0000 0x2008>,
				      <0x0aeac000 0xf0>;
				reg-names = "mdp_phys",
					"vbif_phys",
					"regdma_phys";

				power-domains = <&clock_dispcc 0>;
				clocks =
					<&gcc GCC_DISP_AHB_CLK>,
					<&gcc GCC_DISP_AXI_CLK>,
					<&clock_dispcc DISP_CC_MDSS_AHB_CLK>,
					<&clock_dispcc DISP_CC_MDSS_AXI_CLK>,
					<&clock_dispcc DISP_CC_MDSS_MDP_CLK>,
					<&clock_dispcc DISP_CC_MDSS_VSYNC_CLK>;
				clock-names = "gcc_iface", "gcc_bus", "iface_clk",
						"bus_clk", "core_clk", "vsync_clk";
				clock-rate = <0 0 0 0 300000000 19200000 0>;
				clock-max-rate = <0 0 0 0 412500000 19200000 0>;

				/*dpu-vdd-supply = <&mdss_core_gdsc>;*/

				/* interrupt config */
				interrupt-parent = </*&pdc*/>;
				interrupts = <0 83 0>;
				interrupt-controller;
				#interrupt-cells = <1>;
				iommus = <&apps_smmu 0x880 0x8>,
					<&apps_smmu 0xc80 0x8>;

				#address-cells = <1>;
				#size-cells = <0>;

				#power-domain-cells = <0>;

				qcom,dpu-dram-channels = <2>;
				qcom,dpu-num-nrt-paths = <0>;

				qcom,platform-supply-entries {
					#address-cells = <1>;
					#size-cells = <0>;

					qcom,platform-supply-entry@0 {
						reg = <0>;
						qcom,supply-name = "dpu-vdd";
						qcom,supply-min-voltage = <0>;
						qcom,supply-max-voltage = <0>;
						qcom,supply-enable-load = <0>;
						qcom,supply-disable-load = <0>;
					};
				};

				/* data and reg bus scale settings */
				qcom,dpu-data-bus {
					qcom,msm-bus,name = "mdss_dpu_mnoc";
					qcom,msm-bus,num-cases = <3>;
					qcom,msm-bus,num-paths = <2>;
					qcom,msm-bus,vectors-KBps =
					    <22 773 0 0>, <23 773 0 0>,
					    <22 773 0 6400000>, <23 773 0 6400000>,
					    <22 773 0 6400000>, <23 773 0 6400000>;
				};

				qcom,dpu-llcc-bus {
					qcom,msm-bus,name = "mdss_dpu_llcc";
					qcom,msm-bus,num-cases = <3>;
					qcom,msm-bus,num-paths = <1>;
					qcom,msm-bus,vectors-KBps =
					    <132 770 0 0>,
					    <132 770 0 6400000>,
					    <132 770 0 6400000>;
				};

				qcom,dpu-ebi-bus {
					qcom,msm-bus,name = "mdss_dpu_ebi";
					qcom,msm-bus,num-cases = <3>;
					qcom,msm-bus,num-paths = <1>;
					qcom,msm-bus,vectors-KBps =
					    <129 512 0 0>,
					    <129 512 0 6400000>,
					    <129 512 0 6400000>;
				};

				qcom,dpu-reg-bus {
					qcom,msm-bus,name = "mdss_reg";
					qcom,msm-bus,num-cases = <4>;
					qcom,msm-bus,num-paths = <1>;
					qcom,msm-bus,active-only;
					qcom,msm-bus,vectors-KBps =
						<1 590 0 0>,
						<1 590 0 76800>,
						<1 590 0 150000>,
						<1 590 0 300000>;
				};

				ports {
					#address-cells = <1>;
					#size-cells = <0>;

					port@0 {
						reg = <0>;
						mdp5_intf1_out: endpoint {
							remote-endpoint = <&dsi0_in>;
						};
					};

					port@1 {
						reg = <1>;
						mdp5_intf2_out: endpoint {
							remote-endpoint = <&dsi1_in>;
						};
					};
				};

			};

			dsi0: dsi@ae94000 {
				compatible = "qcom,mdss-dsi-ctrl";
				reg = <0xae94000 0x400>;
				reg-names = "dsi_ctrl";

				interrupt-parent = <&mdss_mdp>;
				interrupts = <4 0>;

				clocks = <&clock_dispcc DISP_CC_MDSS_BYTE0_CLK>,
					 <&clock_dispcc DISP_CC_MDSS_BYTE0_INTF_CLK>,
					 <&clock_dispcc DISP_CC_MDSS_PCLK0_CLK>,
					 <&clock_dispcc DISP_CC_MDSS_ESC0_CLK>,
					 <&clock_dispcc DISP_CC_MDSS_AHB_CLK>,
					 <&clock_dispcc DISP_CC_MDSS_AXI_CLK>;
				clock-names = "byte_clk",
					      "byte_intf_clk",
					      "pixel_clk",
					      "core_clk",
					      "iface_clk",
					      "bus_clk";

				/* TODO */
				//assigned-clocks = <&clock_dispcc DISP_CC_MDSS_BYTE0_CLK_SRC>,
				//		  <&clock_dispcc DISP_CC_MDSS_PCLK0_CLK_SRC>;
				//assigned-clock-parents = <&dsi0_phy 0>,
				//			 <&dsi0_phy 1>;

				phys = <&dsi0_phy>;
				phy-names = "dsi-phy";

				#address-cells = <1>;
				#size-cells = <0>;

				ports {
					#address-cells = <1>;
					#size-cells = <0>;

					port@0 {
						reg = <0>;
						dsi0_in: endpoint {
							//remote-endpoint = <&mdp5_intf1_out>;
						};
					};

					port@1 {
						reg = <1>;
						dsi0_out: endpoint {
						};
					};
				};
			};

			dsi0_phy: dsi-phy@ae94400 {
				compatible = "qcom,dsi-phy-10nm";
				reg = <0xae94400 0x200>,	/* removed phy lane for now */
				      <0xae94a00 0x1e0>,
					<0xae94600 0x280>;
				reg-names = "dsi_phy",
					    "dsi_pll",
						"dsi_phy_lane";

				#clock-cells = <1>;

				clocks = <&clock_dispcc DISP_CC_MDSS_AHB_CLK>;
				clock-names = "iface_clk";
			};

			dsi1: dsi@ae96000 {
				compatible = "qcom,mdss-dsi-ctrl";
				reg = <0xae96000 0x400>;
				reg-names = "dsi_ctrl";

				interrupt-parent = <&mdss_mdp>;
				interrupts = <5 0>;

				clocks = <&clock_dispcc DISP_CC_MDSS_BYTE1_CLK>,
					 <&clock_dispcc DISP_CC_MDSS_BYTE1_INTF_CLK>,
					 <&clock_dispcc DISP_CC_MDSS_PCLK1_CLK>,
					 <&clock_dispcc DISP_CC_MDSS_ESC1_CLK>,
					 <&clock_dispcc DISP_CC_MDSS_AHB_CLK>,
					 <&clock_dispcc DISP_CC_MDSS_AXI_CLK>;
				clock-names = "byte_clk",
					      "byte_intf_clk",
					      "pixel_clk",
					      "core_clk",
					      "iface_clk",
					      "bus_clk";

				//assigned-clocks = <&clock_dispcc DISP_CC_MDSS_BYTE1_CLK_SRC>,
				//		  <&clock_dispcc DISP_CC_MDSS_PCLK1_CLK_SRC>;
				//assigned-clock-parents = <&dsi0_phy 0>,
				//			 <&dsi0_phy 1>;

				phys = <&dsi1_phy>;
				phy-names = "dsi-phy";

				#address-cells = <1>;
				#size-cells = <0>;

				ports {
					#address-cells = <1>;
					#size-cells = <0>;

					port@0 {
						reg = <0>;
						dsi1_in: endpoint {
							//remote-endpoint = <&mdp5_intf2_out>;
						};
					};

					port@1 {
						reg = <1>;
						dsi1_out: endpoint {
						};
					};
				};
			};

			dsi1_phy: dsi-phy@ae96400 {
				compatible = "qcom,dsi-phy-10nm";
				reg = <0xae96400 0x200>,
				      <0xae96a00 0x10e>,
					<0xae96600 0x280>;
				reg-names = "dsi_phy",
					    "dsi_pll",
						"dsi_phy_lane";

				#clock-cells = <1>;

				clocks = <&clock_dispcc DISP_CC_MDSS_AHB_CLK>;
				clock-names = "iface_clk";
			};
		};

		qcom,rmtfs_sharedmem@0 {
			compatible = "qcom,sharedmem-uio";
			reg = <0x0 0x200000>;
			reg-names = "rmtfs";
			qcom,client-id = <0x00000001>;
			qcom,guard-memory;
		};
	};
};

&apps_rsc {
	clock_rpmh: qcom,rpmhclk {
		compatible = "qcom,rpmh-clk-sdm845";
		#clock-cells = <1>;
	};
};

#include "sdm845-dpu-pll.dtsi"
#include "sdm845-dpu.dtsi"
#include "pmi8998.dtsi"
#include "sdm845-pinctrl.dtsi"
#include "sdm845-regulator.dtsi"
#include "sdm845-bus.dtsi"
